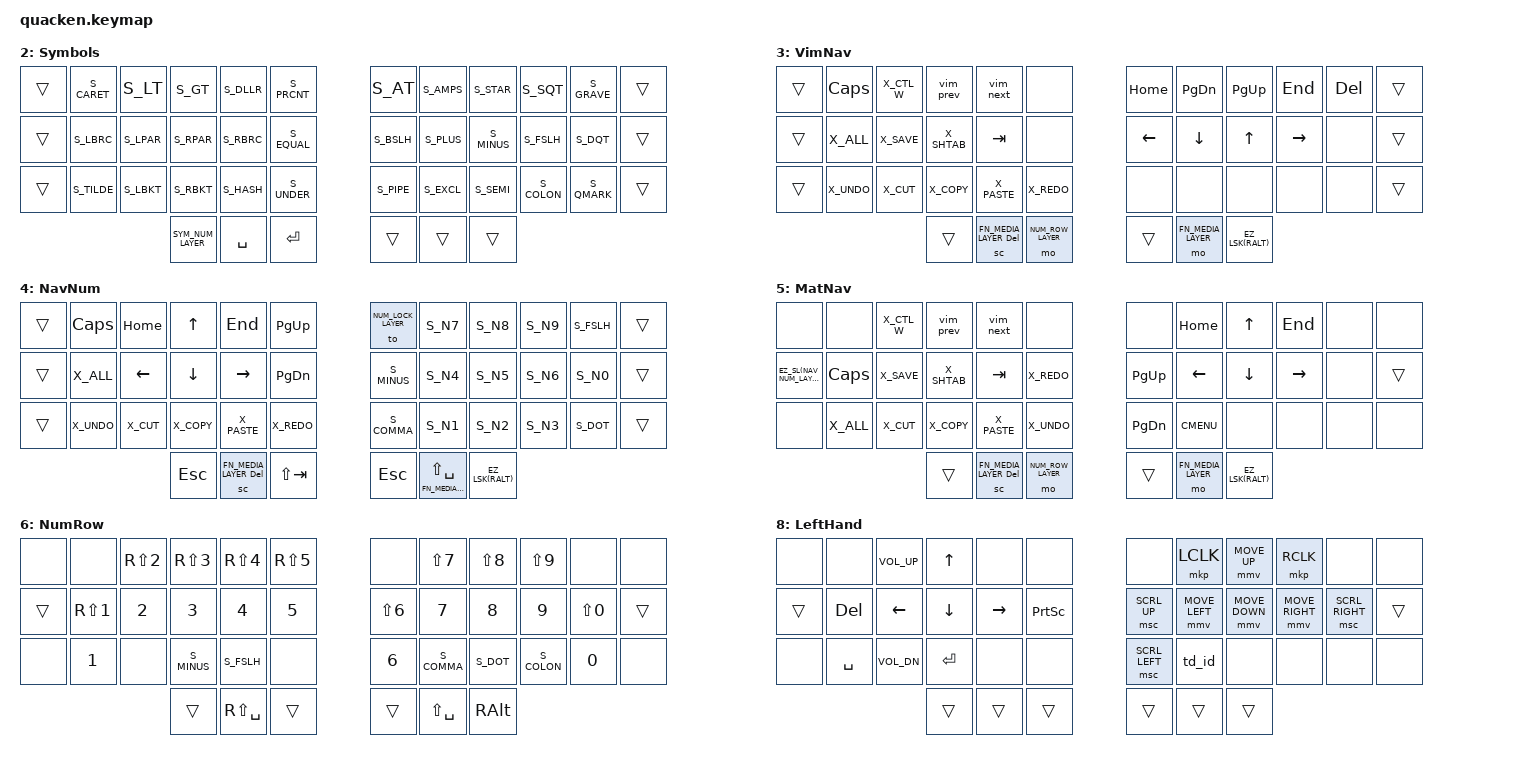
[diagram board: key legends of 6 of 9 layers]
// Selenium keymap:
// https://github.com/OneDeadKey/selenium

#ifndef CI_IGNORE_USER_SETTINGS
  #include "settings.h"   // user settings, ignored by CI tests
#endif

#include "aliases.h"      // symbols, actions, non-ASCII chars
#include "mappings.dtsi"  // key mapping helpers and macros
#include "hold_taps.dtsi" // thumb keys and homerow mods
#include <dt-bindings/zmk/pointing.h> // Necessary for mouse stuff

/ {

  // Define a couple of macros for a tap dance for n o m s et autres
  macros {
    macro_p: macro_p {
        compatible = "zmk,behavior-macro";
        #binding-cells = <0>;
        wait-ms = <30>;
        tap-ms = <30>;
        bindings = <&kp LS(U) &kp A &kp K &kp M &kp L &kp H &kp I &kp D>;
      };

      macro_n: macro_n {
        compatible = "zmk,behavior-macro";
        #binding-cells = <0>;
        wait-ms = <30>;
        tap-ms = <30>;
        bindings = <&kp LS(U) &kp E &kp SEMICOLON &kp S &kp S &kp D &kp K>;
      };

      macro_pn: macro_pn {
        compatible = "zmk,behavior-macro";
        #binding-cells = <0>;
        wait-ms = <30>;
        tap-ms = <30>;
        bindings = <&macro_p>, <&kp SPACE>, <&macro_n>;
      };

      macro_ml: macro_ml {
        compatible = "zmk,behavior-macro";
        #binding-cells = <0>;
        wait-ms = <50>;
        tap-ms = <50>;
        bindings 
          = <&kp U &kp A &kp K &kp M &kp L &kp H &kp I &kp D>
          , <&kp N>
          , <&kp U &kp E &kp SEMICOLON &kp S &kp S &kp D &kp> 
          , <K S_AT>
          , <&kp D &kp R &kp L &kp W &kp D &kp F &kp K &kp J &kp D>
          , <&kp N> 
          , <&kp U &kp S &kp G>
          , <&kp N> 
          , <&kp E &kp J &kp COMMA>;
      };  
    };


  keymap {
    compatible = "zmk,keymap";

    // 0. Base layer -- keep the QWERTY key codes to use your OS keyboard layout
    //               -- the Space Cadet layer-tap on the right can be replaced by an AltGr/Enter mod-tap
    //               -- adjust the homerow mods with the #define statements above
    base_layer: base_layer {
      display-name = "Base";
      bindings = <
        &none                     &kp Q  &kp W  &kp E  &kp R  &kp T        &kp Y  &kp U  &kp I     &kp O   &kp P      &none
        &EZ_SL(LEFT_MOUSE_LAYER)  HRM_A  HRM_S  HRM_D  HRM_F  &kp G        &kp H  HRM_J  HRM_K     HRM_L   HRM_SEMI   &lt FN_MEDIA_LAYER SPACE
        &EZ_SL(NAV_NUM_LAYER)     &kp Z  &kp X  &kp C  &kp V  &kp B        &kp N  &kp M  &kp COMMA &kp DOT &kp FSLH   &tp_num_lock
            LTHUMB_TUCK  LTHUMB_HOME  LTHUMB_REACH    RTHUMB_REACH         RTHUMB_HOME  RTHUMB_TUCK
      >;
    };

    // 1. NumLock layer -- NavNum layer that stays on until deactivated without holding key
    num_lock_layer: num_lock_layer {
      display-name = "NumLock";
      bindings = <
        &trans  S_MONEY  &kp HOME &kp UP   &kp END   S_PRCNT      S_DOT           S_N7  S_N8  S_N9  S_COMMA  &trans
        &trans  &kp ESC  &kp LEFT &kp DOWN &kp RIGHT &kp PG_UP    &to BASE_LAYER  S_N4  S_N5  S_N6  S_FSLH   &trans
        &trans  S_EQUAL  S_COLON  S_STAR   S_PLUS    &kp PG_DN    S_MINUS         S_N1  S_N2  S_N3  S_N0     &trans
                &trans  &sc NAV_NUM_LAYER BACKSPACE  &kp (TAB)    &trans  &lt NAV_NUM_LAYER LS(SPACE)  &EZ_SL(SYMBOLS_LAYER)
      >;
    };

    // 2. Symbols layer -- with Ergo-L, basically just an AltGr layer with custom thumb keys
    //                  -- can be redefined for non-AltGr layouts such as QWERTY-ANSI
    symbols_layer: symbols_layer {
      display-name = "Symbols";
      bindings = <
        &trans  S_CARET S_LT    S_GT    S_DLLR  S_PRCNT       S_AT    S_AMPS  S_STAR  S_SQT   S_GRAVE  &trans
        &trans  S_LBRC  S_LPAR  S_RPAR  S_RBRC  S_EQUAL       S_BSLH  S_PLUS  S_MINUS S_FSLH  S_DQT    &trans
        &trans  S_TILDE S_LBKT  S_RBKT  S_HASH  S_UNDER       S_PIPE  S_EXCL  S_SEMI  S_COLON S_QMARK  &trans
                    SYM_NUM_LAYER  &kp SPACE  &kp ENTER       &trans  &trans  &trans
      >;
    };

    // 3. VimNav layer -- HJKL arrow cluster on the right hand
    //                 -- best used along with the NumRow layer
    //                  -- keyboard shortcuts on the left hand are adjusted to the OS layout (Ergo-L here)
    vim_nav_layer: vim_nav_layer {
      display-name = "VimNav";
      bindings = <
        &trans  &kp CAPS X_CTL_W  &vim_prev &vim_next &none        &kp HOME &kp PG_DN &kp PG_UP &kp END   &kp DEL &trans
        &trans  X_ALL    X_SAVE   X_SHTAB   &kp TAB   &none        &kp LEFT &kp DOWN  &kp UP    &kp RIGHT &none   &trans
        &trans  X_UNDO   X_CUT    X_COPY    X_PASTE   X_REDO       &none    &none     &none     &none     &none   &trans
          &trans  &sc FN_MEDIA_LAYER DEL  &mo NUM_ROW_LAYER        &trans  &mo FN_MEDIA_LAYER  &EZ_LSK(RALT)
      >;
    };

    // 4. NavNum layer -- inverted T arrow cluster on the left hand, numpad on the right hand
    //                 -- can be the only extra layer you need if you're not too picky with number+symbols n-grams
    //                 -- keyboard shortcuts on the left hand are adjusted to the OS layout (Ergo-L here)
    nav_num_layer: nav_num_layer {
      display-name = "NavNum";
      bindings = <
        &trans  &kp CAPS  &kp HOME &kp UP   &kp END   &kp PG_UP   &to NUM_LOCK_LAYER S_N7  S_N8  S_N9  S_FSLH  &trans
        &trans  X_ALL    &kp LEFT &kp DOWN &kp RIGHT &kp PG_DN    S_MINUS            S_N4  S_N5  S_N6  S_N0    &trans
        &trans  X_UNDO   X_CUT    X_COPY   X_PASTE   X_REDO       S_COMMA            S_N1  S_N2  S_N3  S_DOT   &trans
                &kp ESC  &sc FN_MEDIA_LAYER DEL  &kp LS(TAB)    &kp ESCAPE  &lt FN_MEDIA_LAYER LS(SPACE)  &EZ_LSK(RALT)
      >;
    };

    // 5. NavNav layer  -- a mix between the vimnav and numnav layer
    //                  -- keeps the powerful left block of VimNav
    //                  -- has a cluster of arrows more similar to NavNum, for non vim users
    //                  -- to be use with the NumRow, as an alternative to VimNav
    matnav_layer: matnav_layer {
      display-name = "MatNav";
      bindings = <
        &none                  &none     X_CTL_W  &vim_prev &vim_next   &none           &none      &kp HOME     &kp UP     &kp END    &none   &none
        &EZ_SL(NAV_NUM_LAYER)  &kp CAPS  X_SAVE   X_SHTAB   &kp TAB     X_REDO          &kp PG_UP  &kp LEFT     &kp DOWN   &kp RIGHT  &none   &trans
        &none                  X_ALL     X_CUT    X_COPY    X_PASTE     X_UNDO          &kp PG_DN  &kp K_CMENU  &none      &none      &none   &none
                               &trans  &sc FN_MEDIA_LAYER DEL  &mo NUM_ROW_LAYER           &trans  &mo FN_MEDIA_LAYER  &EZ_LSK(RALT)
      >;
    };
  
    // 6. NumRow layer -- bring the numbers to the homerow, keep shift+numbers for shortcuts and symbols
    //                 -- space becomes shift+space, which is a no-break space with some OS layouts (e.g. Ergo-L)
    //                 -- best used along with the VimNav layer
    num_row_layer: num_row_layer {
      display-name = "NumRow";
      bindings = <
        &none   &none       &kp RS(N2) &kp RS(N3) &kp RS(N4) &kp RS(N5)       &none       &kp LS(N7) &kp LS(N8) &kp LS(N9) &none       &none
        &trans  &kp RS(N1)  &kp N2     &kp N3     &kp N4     &kp N5           &kp LS(N6)  &kp N7     &kp N8     &kp N9     &kp LS(N0)  &trans
        &none   &kp N1      &none      S_MINUS    S_FSLH     &none            &kp N6      S_COMMA    S_DOT      S_COLON    &kp N0      &none
                                      &trans  &kp RS(SPACE) &trans            &trans  &kp LS(SPACE) &kp RALT
      >;
    };

    // 7. FnMedia layer -- F1..12 pad on the left hand, HRM on the right hand
    //                  -- reset and bootloader reset on difficult thumb keys
    //                  -- could be completed with other rare keys
    fn_media_layer: fn_media_layer {
      display-name = "FnMedia";
      bindings = <
        &none   &none   &kp F2   &kp F3   &kp F4  &none           &none                &kp C_PREV  &kp C_VOL_UP  &kp C_BRI_UP   &none         &none
        &trans  &kp F1  &kp F7   &kp F8   &kp F9  &kp F5          &to NUM_LOCK_LAYER   H_J C_PP    H_K C_MUTE    H_L INS        H_SEMI PSCRN  &trans
        &none   &kp F6  &kp F11  &kp F12  &none   &kp F10         &none                &kp C_NEXT  &kp C_VOL_DN  &kp C_BRI_DN   &none         &none
                                &trans  &trans  &bootloader       &sys_reset  &trans  &studio_unlock
      >;
    };

    // 7. Left-hand layer   -- some useful keys for when using the mouse (not a miror layer)
    //                      -- try out alternative shape for volume
    //                      -- test some mouse actions as well. Might go to other layer… or not if I like it.
    left_hand_layer: left_hand_layer {
      display-name = "LeftHand";
        bindings = <
          &none   &none      &kp C_VOL_UP   &kp UP    &none      &none         &none           &mkp LCLK       &mmv MOVE_UP    &mkp RCLK        &none            &none  
          &trans  &kp DEL    &kp LEFT       &kp DOWN  &kp RIGHT  &kp PSCRN     &msc SCRL_UP    &mmv MOVE_LEFT  &mmv MOVE_DOWN  &mmv MOVE_RIGHT  &msc SCRL_RIGHT  &trans
          &none   &kp SPACE  &kp C_VOL_DN   &kp ENTER &none      &none         &msc SCRL_LEFT  &td_id          &none           &none            &none            &none  
                                            &trans  &trans  &trans             &trans  &trans  &trans
        >;
      };
  };
};

// Emulated layouts (experimental!)
#ifdef KB_EMULATION_DVORAK
  #include "emulations/dvorak.dtsi"
#elif defined KB_EMULATION_ERGOL
  #include "emulations/ergol.dtsi"
#elif defined KB_EMULATION_QWERTY_LAFAYETTE
  #include "emulations/qwerty_lafayette.dtsi"

// Some layouts require extra layers to fit on the Quacken.
#elif defined KB_LAYOUT_AZERTY
  #include "extra_layers/azerty.dtsi"
#elif defined KB_LAYOUT_BEPO
  #include "extra_layers/bepo.dtsi"
#elif defined KB_LAYOUT_ERGOL && defined HUMMINGBIRD
  #include "extra_layers/ergol_hummingbird.dtsi"
#elif defined KB_LAYOUT_ERGOL && defined CHEVECHETTE
  #include "extra_layers/ergol_chevechette.dtsi"
#elif defined KB_LAYOUT_ERGOL && defined MARTINET
  #include "extra_layers/ergol_martinet.dtsi"
  #elif defined KB_LAYOUT_ERGOL && defined HIRONDELLE
  #include "extra_layers/ergol_hirondelle.dtsi"
#endif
